VERSION ""

NS_ :

BS_:

BU_:

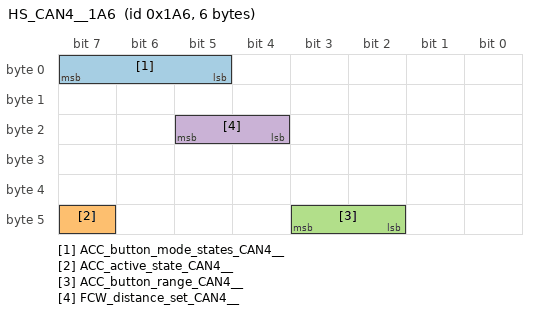
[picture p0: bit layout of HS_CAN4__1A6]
BO_ 422 HS_CAN4__1A6: 6 Vector__XXX
 SG_ ACC_button_mode_states_CAN4__ : 7|3@0+ (1,0) [0|7] "" Vector__XXX
 SG_ ACC_active_state_CAN4__ : 47|1@0+ (1,0) [0|0] "" Vector__XXX
 SG_ ACC_button_range_CAN4__ : 43|2@0+ (1,0) [0|3] "" Vector__XXX
 SG_ FCW_distance_set_CAN4__ : 21|2@0+ (1,0) [0|3] "" Vector__XXX

BO_ 862 HS_CAN4__35E: 2 Vector__XXX
 SG_ LDW_disable_CAN4__ : 11|1@0+ (1,0) [0|0] "" Vector__XXX
